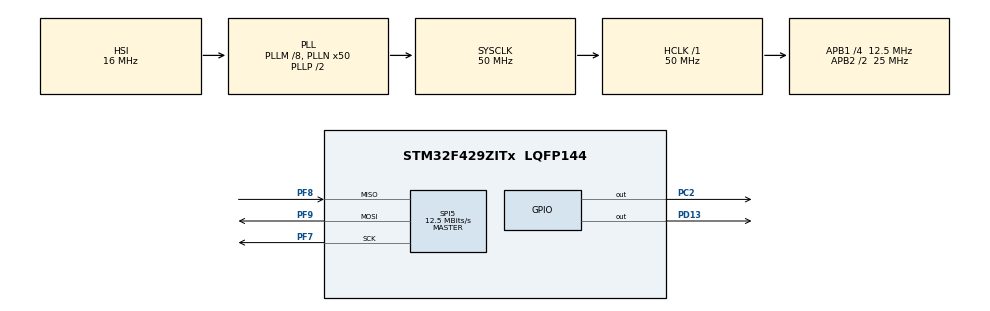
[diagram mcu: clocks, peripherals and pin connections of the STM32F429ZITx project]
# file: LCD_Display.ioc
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Mcu.Family=STM32F4
Mcu.Name=STM32F429ZITx
Mcu.Package=LQFP144
NVIC.PriorityGroup=NVIC_PRIORITYGROUP_4
PC2.Signal=GPIO_Output
PD13.Signal=GPIO_Output
PF7.Mode=Full_Duplex_Master
PF7.Signal=SPI5_SCK
PF8.Mode=Full_Duplex_Master
PF8.Signal=SPI5_MISO
PF9.Mode=Full_Duplex_Master
PF9.Signal=SPI5_MOSI
ProjectManager.HeapSize=0x200
ProjectManager.StackSize=0x400
ProjectManager.TargetToolchain=MDK-ARM V5
RCC.48MHZClocksFreq_Value=25000000
RCC.AHBFreq_Value=50000000
RCC.APB1CLKDivider=RCC_HCLK_DIV4
RCC.APB1Freq_Value=12500000
RCC.APB1TimFreq_Value=25000000
RCC.APB2CLKDivider=RCC_HCLK_DIV2
RCC.APB2Freq_Value=25000000
RCC.APB2TimFreq_Value=50000000
RCC.CortexFreq_Value=50000000
RCC.HCLKFreq_Value=50000000
RCC.HSE_VALUE=8000000
RCC.HSI_VALUE=16000000
RCC.LSE_VALUE=32768
RCC.PLLM=8
RCC.PLLN=50
RCC.PLLSAIDivR=RCC_PLLSAIDIVR_4
RCC.PLLSAIN=60
RCC.PLLSAIR=5
RCC.SYSCLKFreq_VALUE=50000000
RCC.SYSCLKSource=RCC_SYSCLKSOURCE_PLLCLK
RCC.VCOOutputFreq_Value=100000000
SPI5.CalculateBaudRate=12.5 MBits/s
SPI5.Direction=SPI_DIRECTION_2LINES
SPI5.Mode=SPI_MODE_MASTER
SPI5.VirtualType=VM_MASTER
board=32F429IDISCOVERY

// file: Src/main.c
/* USER CODE BEGIN Header */
/**
  ******************************************************************************
  * @file           : main.c
  * @brief          : Main program body
  ******************************************************************************
  * @attention
  *
  * <h2><center>&copy; Copyright (c) 2020 STMicroelectronics.
  * All rights reserved.</center></h2>
  *
  * This software component is licensed by ST under BSD 3-Clause license,
  * the "License"; You may not use this file except in compliance with the
  * License. You may obtain a copy of the License at:
  *                        opensource.org/licenses/BSD-3-Clause
  *
  ******************************************************************************
  */
/* USER CODE END Header */

#include "main.h"
#include "spi.h"
#include "gpio.h"

void SystemClock_Config(void);

int main(void)
{

  /* MCU Configuration--------------------------------------------------------*/

  /* Reset of all peripherals, Initializes the Flash interface and the Systick. */
  HAL_Init();

  /* Configure the system clock */
  SystemClock_Config();

  /* Initialize all configured peripherals */
  MX_GPIO_Init();
  MX_SPI5_Init();
  /* USER CODE BEGIN 2 */
	ILI9341_Init();
	ILI9341_setRotation(3);

	ILI9341_Fill(COLOR_WHITE);

	//Draw and fill circle
	ILI9341_drawCircle(50,50, 40, COLOR_GREEN);
	ILI9341_fillCircle(110,190, 80, COLOR_RED);
  /* USER CODE END 2 */

  /* Infinite loop */
  while (1)
  {

  }
}

void SystemClock_Config(void)
{
  RCC_OscInitTypeDef RCC_OscInitStruct = {0};
  RCC_ClkInitTypeDef RCC_ClkInitStruct = {0};

  /** Configure the main internal regulator output voltage
  */
  __HAL_RCC_PWR_CLK_ENABLE();
  __HAL_PWR_VOLTAGESCALING_CONFIG(PWR_REGULATOR_VOLTAGE_SCALE3);
  /** Initializes the CPU, AHB and APB busses clocks
  */
  RCC_OscInitStruct.OscillatorType = RCC_OSCILLATORTYPE_HSI;
  RCC_OscInitStruct.HSIState = RCC_HSI_ON;
  RCC_OscInitStruct.HSICalibrationValue = RCC_HSICALIBRATION_DEFAULT;
  RCC_OscInitStruct.PLL.PLLState = RCC_PLL_ON;
  RCC_OscInitStruct.PLL.PLLSource = RCC_PLLSOURCE_HSI;
  RCC_OscInitStruct.PLL.PLLM = 8;
  RCC_OscInitStruct.PLL.PLLN = 50;
  RCC_OscInitStruct.PLL.PLLP = RCC_PLLP_DIV2;
  RCC_OscInitStruct.PLL.PLLQ = 4;
  if (HAL_RCC_OscConfig(&RCC_OscInitStruct) != HAL_OK)
  {
    Error_Handler();
  }
  /** Initializes the CPU, AHB and APB busses clocks
  */
  RCC_ClkInitStruct.ClockType = RCC_CLOCKTYPE_HCLK|RCC_CLOCKTYPE_SYSCLK
                              |RCC_CLOCKTYPE_PCLK1|RCC_CLOCKTYPE_PCLK2;
  RCC_ClkInitStruct.SYSCLKSource = RCC_SYSCLKSOURCE_PLLCLK;
  RCC_ClkInitStruct.AHBCLKDivider = RCC_SYSCLK_DIV1;
  RCC_ClkInitStruct.APB1CLKDivider = RCC_HCLK_DIV4;
  RCC_ClkInitStruct.APB2CLKDivider = RCC_HCLK_DIV2;

  if (HAL_RCC_ClockConfig(&RCC_ClkInitStruct, FLASH_LATENCY_1) != HAL_OK)
  {
    Error_Handler();
  }
}

/* USER CODE BEGIN 4 */
//1. Write Command to LCD
void ILI9341_SendCommand(uint8_t com)
{

	HAL_GPIO_WritePin ( GPIOD , GPIO_PIN_13 ,  GPIO_PIN_RESET ) ;
	HAL_SPI_Transmit(&hspi5, &com, 1, 300);

}

//2. Write data to LCD
void ILI9341_SendData(uint8_t data)
{

	HAL_GPIO_WritePin ( GPIOD , GPIO_PIN_13 ,  GPIO_PIN_SET ) ;
	HAL_SPI_Transmit(&hspi5, &data, 1, 300);

}
/* USER CODE END 4 */

void Error_Handler(void)
{
}

/************************ (C) COPYRIGHT STMicroelectronics *****END OF FILE****/
